# CH585SFR register map
Vendor: WCH Ltd.; Series: CH58x; File version: 1.0
CPU: RISC-V r0p0, little endian, no MPU, no FPU, 2 interrupt priority bits
Registers are 8-bit, Read or Write, reset 0x0 unless marked. A register's access mark holds for its fields unless they carry their own. Offsets are from the block's base; [hi:lo] are bit positions.

## GPIO — General porpose intput output
Base 0x40001000
0x90 R16_PA_INT_EN 16-bit — RW, GPIO PA interrupt enable
  [15:0] R16_PA_INT_EN — GPIO PA interrupt enable
0x92 R16_PB_INT_EN 16-bit — RW, GPIO PB interrupt enable
  [15:0] R16_PB_INT_EN — GPIO PB interrupt enable
0x94 R16_PA_INT_MODE 16-bit — RW, GPIO PA interrupt mode: 0=level action, 1=edge action
  [15:0] R16_PA_INT_MODE — GPIO PA interrupt mode
0x96 R16_PB_INT_MODE 16-bit — RW, GPIO PB interrupt mode: 0=level action, 1=edge action;RW, status for parallel slave read
  [15:0] R16_PB_INT_MODE — GPIO PB interrupt mode
0x9C R16_PA_INT_IF 16-bit — RW1, GPIO PA interrupt flag
  [15:0] R16_PA_INT_IF — GPIO PA interrupt flag
0x9E R16_PB_INT_IF 16-bit — RW1, GPIO PB interrupt flag
  [15:0] R16_PB_INT_IF — GPIO PB interrupt flag
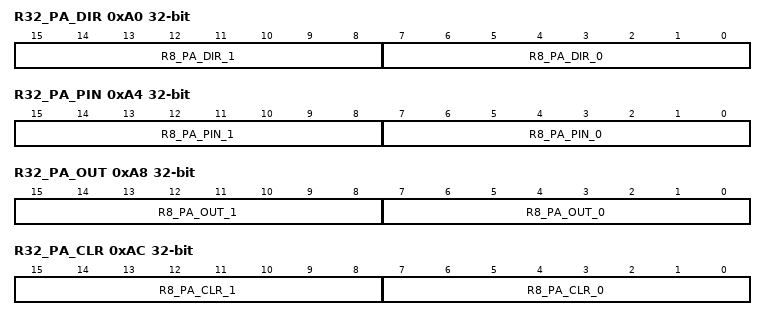
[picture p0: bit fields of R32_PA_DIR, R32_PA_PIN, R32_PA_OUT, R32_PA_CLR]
0xA0 R32_PA_DIR 32-bit — RW, GPIO PA I/O direction: 0=in, 1=out
  [15:8] R8_PA_DIR_1 — GPIO PA I/O direction byte 1
  [7:0] R8_PA_DIR_0 — GPIO PA I/O direction byte 0
0xA4 R32_PA_PIN 32-bit ro reset not defined — RO, GPIO PA input
  [15:8] R8_PA_PIN_1 — GPIO PA input byte 1
  [7:0] R8_PA_PIN_0 — GPIO PA input byte 0
0xA8 R32_PA_OUT 32-bit — RW, GPIO PA output
  [15:8] R8_PA_OUT_1 — GPIO PA output byte 1
  [7:0] R8_PA_OUT_0 — GPIO PA output byte 0
0xAC R32_PA_CLR 32-bit Write — WZ, GPIO PA clear output: 0=keep, 1=clear
  [15:8] R8_PA_CLR_1 — GPIO PA clear output byte 1
  [7:0] R8_PA_CLR_0 — GPIO PA clear output byte 0
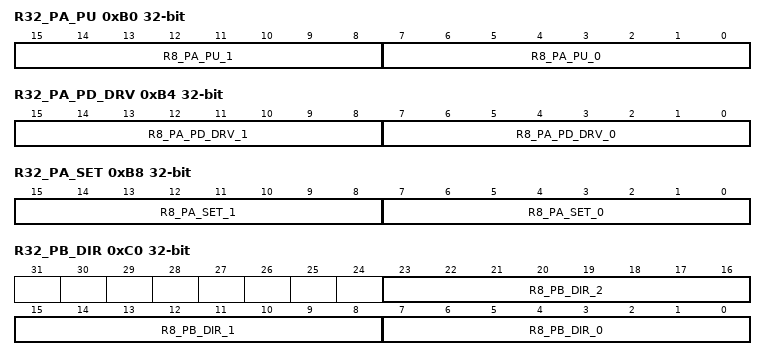
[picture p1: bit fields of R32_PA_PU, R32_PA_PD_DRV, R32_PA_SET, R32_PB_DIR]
0xB0 R32_PA_PU 32-bit — RW, GPIO PA pullup resistance enable
  [15:8] R8_PA_PU_1 — GPIO PA pullup resistance enable byte 0
  [7:0] R8_PA_PU_0 — GPIO PA pullup resistance enable byte 0
0xB4 R32_PA_PD_DRV 32-bit — RW, PA pulldown for input or PA driving capability for output
  [15:8] R8_PA_PD_DRV_1 — PA pulldown for input or PA driving capability for output byte 1
  [7:0] R8_PA_PD_DRV_0 — PA pulldown for input or PA driving capability for output byte 0
0xB8 R32_PA_SET 32-bit — RW, PA port output set register
  [15:8] R8_PA_SET_1 — When the corresponding bit of the set register R3_2PA_SET is 0, the output of the PA pin remains unchanged; When it is 1, the PA pin outputs a high level
  [7:0] R8_PA_SET_0 — When the corresponding bit of the set register R3_2PA_SET is 0, the output of the PA pin remains unchanged; When it is 1, the PA pin outputs a high level
0xC0 R32_PB_DIR 32-bit — RW, GPIO PB I/O direction: 0=in, 1=out
  [23:16] R8_PB_DIR_2 — GPIO PB I/O direction byte 2
  [15:8] R8_PB_DIR_1 — GPIO PB I/O direction byte 1
  [7:0] R8_PB_DIR_0 — GPIO PB I/O direction byte 0
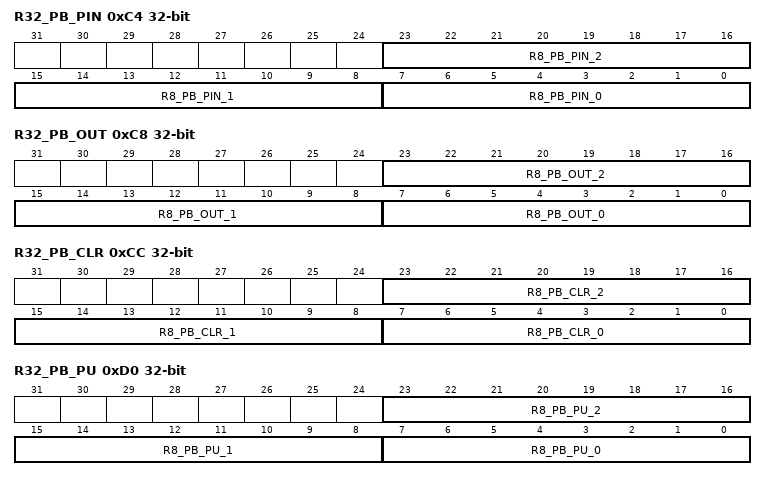
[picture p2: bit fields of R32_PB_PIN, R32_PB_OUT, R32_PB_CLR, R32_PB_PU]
0xC4 R32_PB_PIN 32-bit ro — RO, GPIO PB input
  [23:16] R8_PB_PIN_2 — GPIO PB input byte 2
  [15:8] R8_PB_PIN_1 — GPIO PB input byte 1
  [7:0] R8_PB_PIN_0 — GPIO PB input byte 0
0xC8 R32_PB_OUT 32-bit — RW, GPIO PB output;RW, data for parallel slave read
  [23:16] R8_PB_OUT_2 — GPIO PB output byte 2
  [15:8] R8_PB_OUT_1 — GPIO PB output byte 1
  [7:0] R8_PB_OUT_0 — GPIO PB output byte 0
0xCC R32_PB_CLR 32-bit — WZ, GPIO PB clear output: 0=keep, 1=clear
  [23:16] R8_PB_CLR_2 — GPIO PB clear output byte 2
  [15:8] R8_PB_CLR_1 — GPIO PB clear output byte 1
  [7:0] R8_PB_CLR_0 — GPIO PB clear output byte 0
0xD0 R32_PB_PU 32-bit — RW, GPIO PB pullup resistance enable
  [23:16] R8_PB_PU_2 — GPIO PB pullup resistance enable byte 2
  [15:8] R8_PB_PU_1 — GPIO PB pullup resistance enable byte 1
  [7:0] R8_PB_PU_0 — GPIO PB pullup resistance enable byte 0
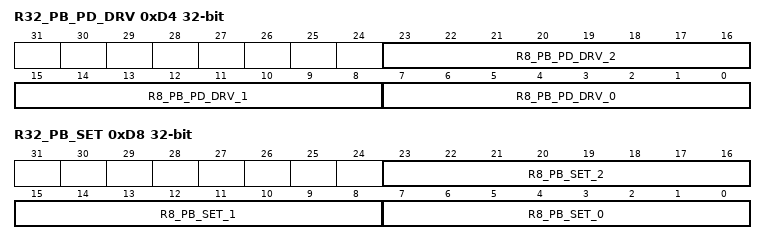
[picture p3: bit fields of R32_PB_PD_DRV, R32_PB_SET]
0xD4 R32_PB_PD_DRV 32-bit — RW, PB pulldown for input or PB driving capability for output
  [23:16] R8_PB_PD_DRV_2 — PB pulldown for input or PB driving capability for output byte 0
  [15:8] R8_PB_PD_DRV_1 — PB pulldown for input or PB driving capability for output byte 0
  [7:0] R8_PB_PD_DRV_0 — PB pulldown for input or PB driving capability for output byte 0
0xD8 R32_PB_SET 32-bit — RW, PB port output set register
  [23:16] R8_PB_SET_2 — When the corresponding bit of the set register R3_2PA_SET is 0, the output of the PA pin remains unchanged; When it is 1, the PA pin outputs a high level
  [15:8] R8_PB_SET_1 — When the corresponding bit of the set register R3_2PA_SET is 0, the output of the PA pin remains unchanged; When it is 1, the PA pin outputs a high level
  [7:0] R8_PB_SET_0 — When the corresponding bit of the set register R3_2PA_SET is 0, the output of the PA pin remains unchanged; When it is 1, the PA pin outputs a high level
